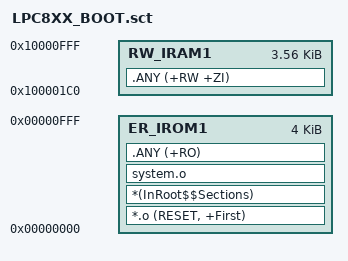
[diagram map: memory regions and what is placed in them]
; *************************************************************
; *** Scatter-Loading Description File generated by uVision ***
; *************************************************************

LR_IROM1 0x00000000 0x00001000  {    ; load region size_region
  ER_IROM1 0x00000000 0x00001000  {  ; load address = execution address
   *.o (RESET, +First)
   *(InRoot$$Sections)
   system.o	
   .ANY (+RO)
  }
  RW_IRAM1 0x100001C0 0x00000E40  {  ; RW data
   .ANY (+RW +ZI)
  }
}

